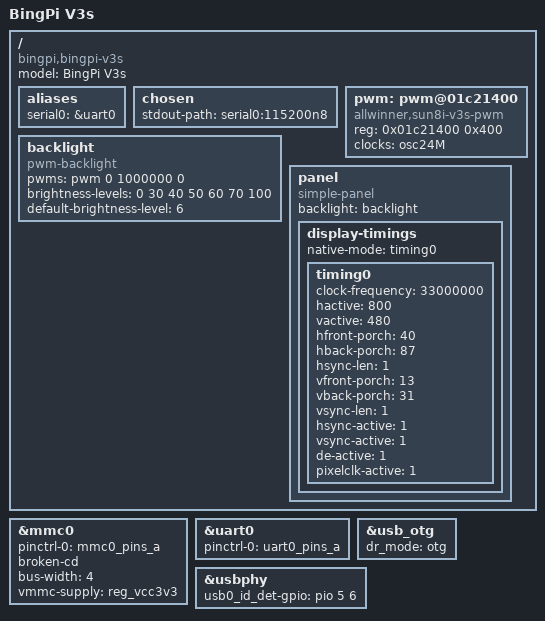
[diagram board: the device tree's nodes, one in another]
/dts-v1/;
#include "sun8i-v3s-uboot.dtsi"
#include "sunxi-common-regulators.dtsi"

/ {
	model = "BingPi V3s";
	compatible = "bingpi,bingpi-v3s", "allwinner,sun8i-v3s";

	aliases {
		serial0 = &uart0;
	};

	chosen {
		stdout-path = "serial0:115200n8";
	};

	pwm: pwm@01c21400 {
		compatible = "allwinner,sun8i-v3s-pwm";
		reg = <0x01c21400 0x400>;
		clocks = <&osc24M>;
		#pwm-cells = <3>;
		status = "okay";
	};

	backlight: backlight {
		compatible = "pwm-backlight";
		pwms = <&pwm 0 1000000 0>;
		brightness-levels = <0 30 40 50 60 70 100>;
		default-brightness-level = <6>;
		status = "okay";
	};

	/*
	 * 800x480 RGB666 panel, timing taken from the LicheePi Zero
	 * U-Boot lcd-mode used by the vendor BSP:
	 * x:800,y:480,depth:18,pclk_khz:33000,le:87,ri:40,up:31,lo:13,
	 * hs:1,vs:1,sync:3,vmode:0
	 */
	panel: panel {
		compatible = "simple-panel";
		backlight = <&backlight>;
		status = "okay";

		display-timings {
			native-mode = <&timing0>;

			timing0: timing0 {
				clock-frequency = <33000000>;
				hactive = <800>;
				vactive = <480>;
				hfront-porch = <40>;
				hback-porch = <87>;
				hsync-len = <1>;
				vfront-porch = <13>;
				vback-porch = <31>;
				vsync-len = <1>;
				hsync-active = <1>;
				vsync-active = <1>;
				de-active = <1>;
				pixelclk-active = <1>;
			};
		};
	};
};

&mmc0 {
	pinctrl-0 = <&mmc0_pins_a>;
	pinctrl-names = "default";
	broken-cd;
	bus-width = <4>;
	vmmc-supply = <&reg_vcc3v3>;
	status = "okay";
};

&uart0 {
	pinctrl-0 = <&uart0_pins_a>;
	pinctrl-names = "default";
	status = "okay";
};

&usb_otg {
	dr_mode = "otg";
	status = "okay";
};

&usbphy {
	usb0_id_det-gpio = <&pio 5 6 GPIO_ACTIVE_HIGH>;
	status = "okay";
};
